# SAM9X60D5M register map
Vendor: Microchip
Registers are 32-bit, read-write, no defined reset value unless marked. A register's access mark holds for its fields unless they carry their own. Addresses are absolute, and some are shared; only a register's first bit layout is shown; [hi:lo] are bit positions; {n}, {i} and the like mark numbered series.

## UHPHS_OHCI
0x600000 UHPHS_OHCI_HcRevision ro
  [7:0] REV — OHCI Revision Number
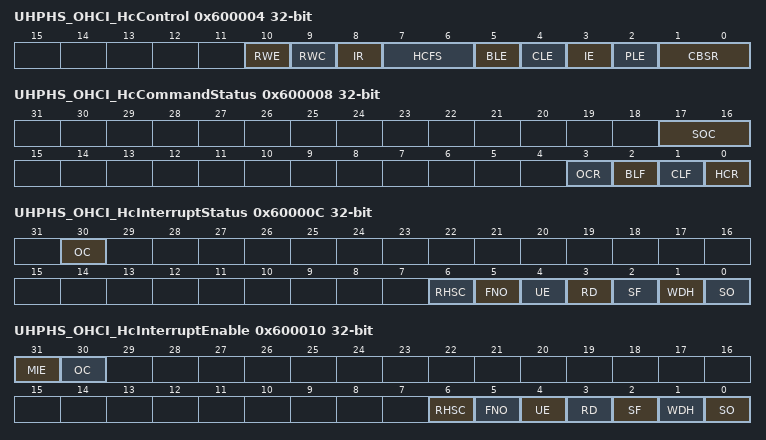
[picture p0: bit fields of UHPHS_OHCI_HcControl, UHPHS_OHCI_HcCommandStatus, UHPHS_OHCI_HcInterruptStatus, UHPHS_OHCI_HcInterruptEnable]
0x600004 UHPHS_OHCI_HcControl
  [10] RWE — Remote Wakeup Enable
  [9] RWC — Remote Wakeup Connected
  [8] IR — Interrupt Routing
  [7:6] HCFS — Host Controller Functional State
  [5] BLE — Bulk List Enable
  [4] CLE — ControL List Enable
  [3] IE — Isochronous Enable
  [2] PLE — Periodic List Enable
  [1:0] CBSR — Control/Bulk Service Ratio
0x600008 UHPHS_OHCI_HcCommandStatus
  [17:16] SOC — Scheduling Overrun Count (read-only)
  [3] OCR — Ownership Change Request (read/write)
  [2] BLF — Bulk List Filled (read/write)
  [1] CLF — Control List Filled (read/write)
  [0] HCR — Host Controller Reset (read/write)
0x60000C UHPHS_OHCI_HcInterruptStatus
  [30] OC — Ownership Change (read-only)
  [6] RHSC — Root Hub Status Change (read/write, write '1' to clear)
  [5] FNO — Frame Number Overflow (read/write, write '1' to clear)
  [4] UE — Unrecoverable Error (read/write, write '1' to clear)
  [3] RD — Resume Detected (read/write, write '1' to clear)
  [2] SF — Start of Frame (read/write, write '1' to clear)
  [1] WDH — Write Done Head (read/write, write '1' to clear)
  [0] SO — Scheduling Overrun (read/write, write '1' to clear)
0x600010 UHPHS_OHCI_HcInterruptEnable
  [31] MIE — Master Interrupt Enable (read/write, write '1' to set)
  [30] OC — Ownership Change (read-only)
  [6] RHSC — Root Hub Status Change (read/write, write '1' to set)
  [5] FNO — Frame Number Overflow (read/write, write '1' to set)
  [4] UE — Unrecoverable Error (read/write, write '1' to set)
  [3] RD — Resume Detected (read/write, write '1' to set)
  [2] SF — Start of Frame (read/write, write '1' to set)
  [1] WDH — Write Done Head (read/write, write '1' to set)
  [0] SO — Scheduling Overrun (read/write, write '1' to set)
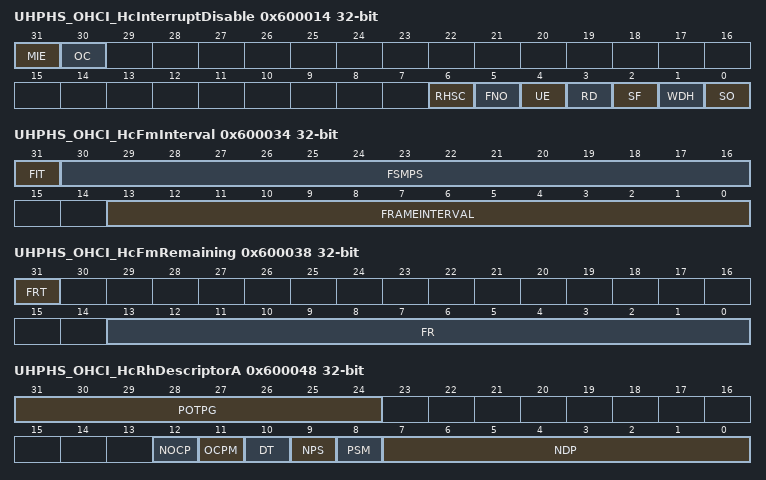
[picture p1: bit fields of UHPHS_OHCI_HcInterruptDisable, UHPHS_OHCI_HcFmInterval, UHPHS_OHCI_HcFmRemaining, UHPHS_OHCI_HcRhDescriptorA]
0x600014 UHPHS_OHCI_HcInterruptDisable
  [31] MIE — Master Interrupt Enable (read/write)
  [30] OC — Ownership Change (read-only)
  [6] RHSC — Root Hub Status Change (read/write)
  [5] FNO — Frame Number Overflow (read/write)
  [4] UE — Unrecoverable Error (read/write)
  [3] RD — Resume Detected (read/write)
  [2] SF — Start of Frame (read/write)
  [1] WDH — Write Done Head (read/write)
  [0] SO — Scheduling Overrun (read/write)
0x600018 UHPHS_OHCI_HcHCCA
  [31:8] HCCA — Physical Address of the Beginning of the HCCA
0x60001C UHPHS_OHCI_HcPeriodCurrentED
  [31:4] PCED — Physical Address of the Current ED on the Periodic ED list
0x600020 UHPHS_OHCI_HcControlHeadED
  [31:4] CHED — Physical Address of the Head ED on the Control ED list
0x600024 UHPHS_OHCI_HcControlCurrentED
  [31:4] CCED — Physical Address of the Current ED on the Control ED List
0x600028 UHPHS_OHCI_HcBulkHeadED
  [31:4] BHED — Physical Address of the Head ED on the Bulk ED List
0x60002C UHPHS_OHCI_HcBulkCurrentED
  [31:4] BCED — Physical Address of the Current ED on the Bulk ED List
0x600030 UHPHS_OHCI_HcDoneHead
  [31:4] DH — Physical Address of the Last TD that has added to the done queue
0x600034 UHPHS_OHCI_HcFmInterval
  [31] FIT — Frame Interval Toggle
  [30:16] FSMPS — Largest Data Packet
  [13:0] FRAMEINTERVAL
0x600038 UHPHS_OHCI_HcFmRemaining
  [31] FRT — Frame Remaining Toggle
  [13:0] FR — Frame Remaining
0x60003C UHPHS_OHCI_HcFmNumber
  [15:0] FN — Frame Number
0x600040 UHPHS_OHCI_HcPeriodicStart
  [13:0] PS — Periodic Start
0x600044 UHPHS_OHCI_HcLSThreshold
  [13:0] LST — Low-Speed Threshold
0x600048 UHPHS_OHCI_HcRhDescriptorA
  [31:24] POTPG — Power-On to Power-good Time (read/write)
  [12] NOCP — No Overcurrent Protection (read/write)
  [11] OCPM — Overcurrent Protection Mode (read/write)
  [10] DT — Device Type (read-only)
  [9] NPS — No Power Switching (read/write)
  [8] PSM — Power Switching Mode (read/write)
  [7:0] NDP — Number of Downstream Ports (read-only)
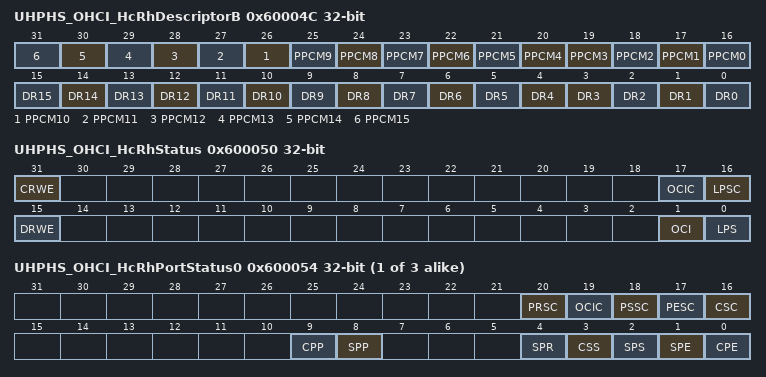
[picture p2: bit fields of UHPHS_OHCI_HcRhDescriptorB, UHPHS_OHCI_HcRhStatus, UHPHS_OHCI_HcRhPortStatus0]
0x60004C UHPHS_OHCI_HcRhDescriptorB
  [n+16] PPCM{n} (n=4..15) — Port Power Control Mask
  [19] PPCM3 — Port Power Control Mask for Downstream Port 3
  [18] PPCM2 — Port Power Control Mask for Downstream Port 2
  [17] PPCM1 — Port Power Control Mask for Downstream Port 1
  [16] PPCM0 — Port Power Control Mask
  [n] DR{n} (n=4..15) — Device Removable
  [3] DR3 — Device Removable Bit for Downstream Port 3
  [2] DR2 — Device Removable Bit for Downstream Port 2
  [1] DR1 — Device Removable Bit for Downstream Port 1
  [0] DR0 — Device Removable
0x600050 UHPHS_OHCI_HcRhStatus
  [31] CRWE — Clear Remote Wakeup Enable (read/write)
  [17] OCIC — Overcurrent Indication Change (read/write)
  [16] LPSC — Local Power Status Change (read/write)
  [15] DRWE — Device Remote Wakeup Enable (read/write)
  [1] OCI — Overcurrent Indicator (read-only)
  [0] LPS — Local Power Status (read/write)
{0x600054+4i} UHPHS_OHCI_HcRhPortStatus{i} (i=0..2)
  [20] PRSC — Port Reset Status Change (read/write, write '1' to clear)
  [19] OCIC — Overcurrent Indicator Change (read/write)
  [18] PSSC — Port Suspend Status Change (read/write, write '1' to clear)
  [17] PESC — Port Enable Status Change (read/write, write '1' to clear)
  [16] CSC — Connect Status Change (read/write, write '1' to clear)
  [9] CPP — Low-speed Device Attached/clear Port Power (read/write)
  [8] SPP — Port Power Status/set Port Power (read/write)
  [4] SPR — Port Reset Status/set Port Reset (read/write)
  [3] CSS — Port Overcurrent Indicator/clear Suspend Status (read/write)
  [2] SPS — Port Suspend Status/set Port Suspend (read/write)
  [1] SPE — Port Enable Status/set Port Enable (read/write)
  [0] CPE — Port Current Connection Status/clear Port Enable (read/write)
